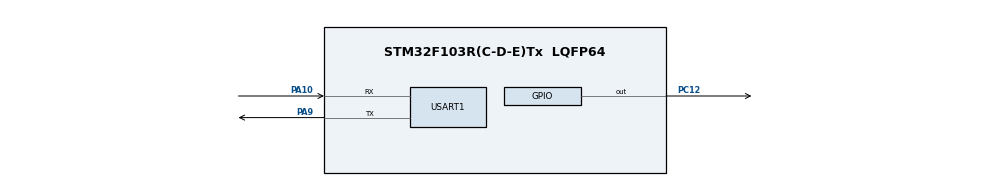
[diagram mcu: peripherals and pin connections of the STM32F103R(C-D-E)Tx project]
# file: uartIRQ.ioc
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Mcu.Family=STM32F1
Mcu.Name=STM32F103R(C-D-E)Tx
Mcu.Package=LQFP64
NVIC.PriorityGroup=NVIC_PRIORITYGROUP_4
NVIC.USART1_IRQn=true\:0\:0\:false\:false\:true\:true\:true\:true
PA10.Mode=Asynchronous
PA10.Signal=USART1_RX
PA9.Mode=Asynchronous
PA9.Signal=USART1_TX
PC12.Signal=GPIO_Output
ProjectManager.HeapSize=0x200
ProjectManager.StackSize=0x400
ProjectManager.TargetToolchain=MDK-ARM V5.32
RCC.APB1Freq_Value=8000000
RCC.APB2Freq_Value=8000000
USART1.VirtualMode=VM_ASYNC
VP_SYS_VS_ND.Mode=No_Debug
board=custom

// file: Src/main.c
/* USER CODE BEGIN Header */
/**
  ******************************************************************************
  * @file           : main.c
  * @brief          : Main program body
  ******************************************************************************
  * @attention
  *
  * Copyright (c) 2022 STMicroelectronics.
  * All rights reserved.
  *
  * This software is licensed under terms that can be found in the LICENSE file
  * in the root directory of this software component.
  * If no LICENSE file comes with this software, it is provided AS-IS.
  *实现简单的串口通信协议，使用io函数时只需要两个函数进行重定向即可
  ******************************************************************************
  */
/* USER CODE END Header */
#include "main.h"

/* USER CODE BEGIN Includes */
#include <stdio.h>
/* USER CODE END Includes */

/* USER CODE BEGIN PD */
#define LENGTH 4  //数据缓冲区长度宏定义

/* USER CODE END PD */

UART_HandleTypeDef huart1;

/* USER CODE BEGIN PV */
uint8_t RxBuffer[LENGTH]; //数据缓冲区
volatile uint8_t RxFlag=0;   //数据接收标志，0表示未接收完成，1接收完成
uint8_t ErrFlag=0;    //指令错误标志，0表示指令正确，1表示指令错
/* USER CODE END PV */

void SystemClock_Config(void);
static void MX_GPIO_Init(void);
static void MX_USART1_UART_Init(void);

int main(void)
{

  /* MCU Configuration--------------------------------------------------------*/

  /* Reset of all peripherals, Initializes the Flash interface and the Systick. */
  HAL_Init();

  /* Configure the system clock */
  SystemClock_Config();

  /* Initialize all configured peripherals */
  MX_GPIO_Init();
  MX_USART1_UART_Init();
  /* USER CODE BEGIN 2 */
	//发送提示信息
printf("******** Communication Protocol *****\n");
printf("Please enter instrution:\n");
printf("Head->0xaa Device->0x01 Operation->0x00/0x01 Tail->0x55.\n");
HAL_UART_Receive_IT(&huart1,(uint8_t*)RxBuffer,LENGTH);//使能接收中断
  /* USER CODE END 2 */

  /* Infinite loop */
  while (1)
  {

    /* USER CODE BEGIN 3 */
		if(RxFlag)
			{
			RxFlag=0;//清除标志
			if(RxBuffer[0]==0xaa && RxBuffer[3]==0x55)
				{//判断帧头帧尾
				if(RxBuffer[1]==0x01)//判断设备码
				{
					if(RxBuffer[2]==0x00)
						{//判断功能码
						HAL_GPIO_WritePin(GPIOC,GPIO_PIN_12,GPIO_PIN_RESET);
							printf("LD2 is close\n");
					}else if(RxBuffer[2]==0x01)
						{
							HAL_GPIO_WritePin(GPIOC,GPIO_PIN_12,GPIO_PIN_SET);
							printf("LD2 is open\n");
					}else{

						ErrFlag=1;
					}
				}else{
					ErrFlag=1;
				}
			}else{
				ErrFlag=1;
			}

			if(ErrFlag){
				printf("Communication Error ! Please send again!\n");
			}
			//清除接收缓冲区和错误标志准备下一次接收
			ErrFlag=0;
			RxBuffer[0]=0;
			RxBuffer[1]=0;
					RxBuffer[2]=0;
					RxBuffer[3]=0;
		}
  }
  /* USER CODE END 3 */
}

void SystemClock_Config(void)
{
  RCC_OscInitTypeDef RCC_OscInitStruct = {0};
  RCC_ClkInitTypeDef RCC_ClkInitStruct = {0};

  /** Initializes the RCC Oscillators according to the specified parameters
  * in the RCC_OscInitTypeDef structure.
  */
  RCC_OscInitStruct.OscillatorType = RCC_OSCILLATORTYPE_HSI;
  RCC_OscInitStruct.HSIState = RCC_HSI_ON;
  RCC_OscInitStruct.HSICalibrationValue = RCC_HSICALIBRATION_DEFAULT;
  RCC_OscInitStruct.PLL.PLLState = RCC_PLL_NONE;
  if (HAL_RCC_OscConfig(&RCC_OscInitStruct) != HAL_OK)
  {
    Error_Handler();
  }

  /** Initializes the CPU, AHB and APB buses clocks
  */
  RCC_ClkInitStruct.ClockType = RCC_CLOCKTYPE_HCLK|RCC_CLOCKTYPE_SYSCLK
                              |RCC_CLOCKTYPE_PCLK1|RCC_CLOCKTYPE_PCLK2;
  RCC_ClkInitStruct.SYSCLKSource = RCC_SYSCLKSOURCE_HSI;
  RCC_ClkInitStruct.AHBCLKDivider = RCC_SYSCLK_DIV1;
  RCC_ClkInitStruct.APB1CLKDivider = RCC_HCLK_DIV1;
  RCC_ClkInitStruct.APB2CLKDivider = RCC_HCLK_DIV1;

  if (HAL_RCC_ClockConfig(&RCC_ClkInitStruct, FLASH_LATENCY_0) != HAL_OK)
  {
    Error_Handler();
  }
}

static void MX_USART1_UART_Init(void)
{

  huart1.Instance = USART1;
  huart1.Init.BaudRate = 115200;
  huart1.Init.WordLength = UART_WORDLENGTH_8B;
  huart1.Init.StopBits = UART_STOPBITS_1;
  huart1.Init.Parity = UART_PARITY_NONE;
  huart1.Init.Mode = UART_MODE_TX_RX;
  huart1.Init.HwFlowCtl = UART_HWCONTROL_NONE;
  huart1.Init.OverSampling = UART_OVERSAMPLING_16;
  if (HAL_UART_Init(&huart1) != HAL_OK)
  {
    Error_Handler();
  }

}

static void MX_GPIO_Init(void)
{
  GPIO_InitTypeDef GPIO_InitStruct = {0};

  /* GPIO Ports Clock Enable */
  __HAL_RCC_GPIOA_CLK_ENABLE();
  __HAL_RCC_GPIOC_CLK_ENABLE();

  /*Configure GPIO pin Output Level */
  HAL_GPIO_WritePin(GPIOC, GPIO_PIN_12, GPIO_PIN_RESET);

  /*Configure GPIO pin : PC12 */
  GPIO_InitStruct.Pin = GPIO_PIN_12;
  GPIO_InitStruct.Mode = GPIO_MODE_OUTPUT_PP;
  GPIO_InitStruct.Pull = GPIO_NOPULL;
  GPIO_InitStruct.Speed = GPIO_SPEED_FREQ_LOW;
  HAL_GPIO_Init(GPIOC, &GPIO_InitStruct);

}

/* USER CODE BEGIN 4 */
void HAL_UART_RxCpltCallback(UART_HandleTypeDef *huart){
	if(huart->Instance==USART1){//判断发生接收中断的串口
		RxFlag=1;//置位数据接收标志
		//重新准备开始下一次的数据接收
		HAL_UART_Receive_IT(&huart1,(uint8_t*)RxBuffer,LENGTH);

	}
}

//串口重定向函数
int fputc(int ch,FILE *f){
	//采用轮询方式发送1字节数据，超时时间设置为无限等待
	HAL_UART_Transmit(&huart1,(uint8_t*)&ch,1,HAL_MAX_DELAY);
	return ch;
}
int fgetc(FILE*f){
	uint8_t ch;
		//采用轮询方式发送1字节数据，超时时间设置为无限等待
	HAL_UART_Receive(&huart1,(uint8_t*)&ch,1,HAL_MAX_DELAY);
	return ch;

}

/* USER CODE END 4 */

void Error_Handler(void)
{
  __disable_irq();
  while (1)
  {
  }
}
